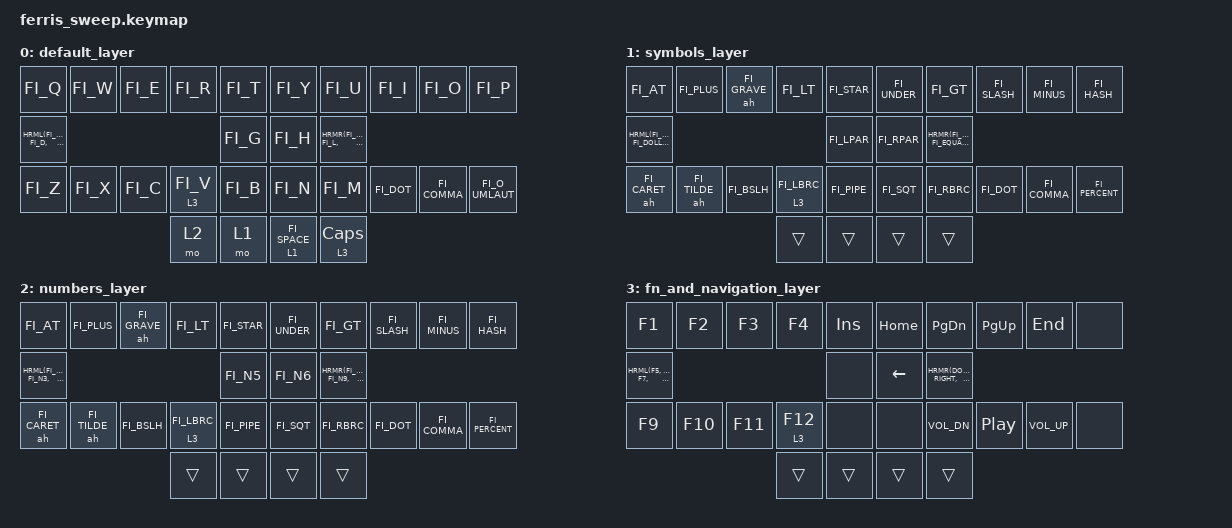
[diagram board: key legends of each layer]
// Copyright (c) 2022 The ZMK Contributors
// SPDX-License-Identifier: MIT

#include <behaviors.dtsi>
#include <dt-bindings/zmk/keys.h>
#include <dt-bindings/zmk/bt.h>
#include <dt-bindings/zmk/outputs.h>
#include "keys_fi.h"

// Home row mods
#define HRML(k1,k2,k3,k4) &ht LSHFT k1  &ht LCTRL k2  &ht LALT  k3  &ht LGUI  k4
#define HRMR(k1,k2,k3,k4) &ht RGUI  k1  &ht RALT  k2  &ht RCTRL k3  &ht RSHFT k4

&caps_word {
    continue-list = <UNDERSCORE MINUS BACKSPACE DELETE>;
};

/ {
    behaviors {
        ht: hold_tap {
            compatible = "zmk,behavior-hold-tap";
            #binding-cells = <2>;
            flavor = "balanced";
            tapping-term-ms = <200>;
            quick-tap-ms = <200>;
            require-prior-idle-ms = <100>;
            bindings = <&kp>, <&kp>;
        };
    };

    combos {
        compatible = "zmk,combos";
        combo_esc {
            timeout-ms = <40>;
            key-positions = <1 2>;
            bindings = <&kp ESC>;
            require-prior-idle-ms = <140>;
        };
        combo_tab {
            timeout-ms = <40>;
            key-positions = <11 12>;
            bindings = <&kp TAB>;
            require-prior-idle-ms = <140>;
        };
        combo_bspc {
            timeout-ms = <40>;
            key-positions = <7 8>;
            bindings = <&kp BSPC>;
            require-prior-idle-ms = <140>;
        };
        combo_enter {
            timeout-ms = <40>;
            key-positions = <17 18>;
            bindings = <&kp ENTER>;
            require-prior-idle-ms = <140>;
        };
        combo_del {
            timeout-ms = <40>;
            key-positions = <27 28>;
            bindings = <&kp DEL>;
            require-prior-idle-ms = <140>;
        };
    };

    macros {
        ah: accent_hack {
            compatible = "zmk,behavior-macro-one-param";
            #binding-cells = <1>;
            bindings = <&macro_param_1to1>, <&kp MACRO_PLACEHOLDER &kp FI_SPACE>;
        };
    };
    keymap {
        compatible = "zmk,keymap";
        default_layer {
            bindings = <
        //╭─────────────┬─────────────┬─────────────┬─────────────┬─────────────╮   ╭─────────────┬─────────────┬─────────────┬─────────────┬─────────────╮
            &kp FI_Q      &kp FI_W      &kp FI_E      &kp FI_R      &kp FI_T          &kp FI_Y      &kp FI_U      &kp FI_I      &kp FI_O      &kp FI_P
        //├─────────────┼─────────────┼─────────────┼─────────────┼─────────────┤   ├─────────────┼─────────────┼─────────────┼─────────────┼─────────────┤
            HRML(FI_A,    FI_S,         FI_D,         FI_F)         &kp FI_G          &kp FI_H      HRMR(FI_J,    FI_K,         FI_L,         FI_A_UMLAUT)
        //├─────────────┼─────────────┼─────────────┼─────────────┼─────────────┤   ├─────────────┼─────────────┼─────────────┼─────────────┼─────────────┤
            &kp FI_Z      &kp FI_X      &kp FI_C      &lt 3 FI_V    &kp FI_B          &kp FI_N      &kp FI_M      &kp FI_DOT    &kp FI_COMMA  &kp FI_O_UMLAUT
        //╰─────────────┴─────────────┴─────────────┼─────────────┼─────────────┤   ├─────────────┼─────────────┼─────────────┴─────────────┴─────────────╯
                                                      &mo 2         &mo 1             &lt 1 FI_SPACE  &lt 3 CAPSLOCK
        //                                          ╰─────────────┴─────────────╯   ╰─────────────┴─────────────╯
            >;
        };

        symbols_layer {
            bindings = <
        //╭─────────────┬─────────────┬─────────────┬─────────────┬─────────────╮   ╭─────────────┬─────────────┬─────────────┬─────────────┬─────────────╮
        //│  @          │  +          │  `          │  <          │   *         │   │  _          │  >          │  /          │  -          │  #          │
            &kp FI_AT     &kp FI_PLUS   &ah FI_GRAVE  &kp FI_LT     &kp FI_STAR       &kp FI_UNDER  &kp FI_GT    &kp FI_SLASH  &kp FI_MINUS   &kp FI_HASH
        //├─────────────┼─────────────┼─────────────┼─────────────┼─────────────┤   ├─────────────┼─────────────┼─────────────┼─────────────┼─────────────┤
        //│  !          │  &          │  $          │  [          │  (          │   │  ]          │  )          │  "          │  =          │  ?          │
            HRML(FI_EXCL, FI_AMPS,      FI_DOLLAR,    FI_LBKT)      &kp FI_LPAR       &kp FI_RPAR   HRMR(FI_RBKT, FI_DQT,       FI_EQUAL,     FI_QMARK)
        //├─────────────┼─────────────┼─────────────┼─────────────┼─────────────┤   ├─────────────┼─────────────┼─────────────┼─────────────┼─────────────┤
        //│  ^          │  ~          │  \          │  {          │  |          │   │  '          │  }          │  .          │  ,          │   %         │
            &ah FI_CARET  &ah FI_TILDE   &kp FI_BSLH  &lt 3 FI_LBRC &kp FI_PIPE       &kp FI_SQT    &kp FI_RBRC   &kp FI_DOT   &kp FI_COMMA  &kp FI_PERCENT
        //╰─────────────┴─────────────┴─────────────┼─────────────┼─────────────┤   ├─────────────┼─────────────┼─────────────┴─────────────┴─────────────╯
                                                      &trans        &trans            &trans        &trans
        //                                          ╰─────────────┴─────────────╯   ╰─────────────┴─────────────╯
            >;
        };

        numbers_layer {
            bindings = <
        //╭─────────────┬─────────────┬─────────────┬─────────────┬─────────────╮   ╭─────────────┬─────────────┬─────────────┬─────────────┬─────────────╮
        //│  @          │  +          │  `          │  <          │   *         │   │  _          │  >          │  /          │  -          │  #          │
            &kp FI_AT     &kp FI_PLUS   &ah FI_GRAVE  &kp FI_LT     &kp FI_STAR       &kp FI_UNDER  &kp FI_GT    &kp FI_SLASH  &kp FI_MINUS   &kp FI_HASH
        //├─────────────┼─────────────┼─────────────┼─────────────┼─────────────┤   ├─────────────┼─────────────┼─────────────┼─────────────┼─────────────┤
        //│  1          │  2          │  3          │  4          │  5          │   │  6          │  7          │  8          │  9          │   0         │
            HRML(FI_N1,   FI_N2,        FI_N3,        FI_N4)        &kp FI_N5         &kp FI_N6     HRMR(FI_N7,   FI_N8,        FI_N9,        FI_N0)
        //├─────────────┼─────────────┼─────────────┼─────────────┼─────────────┤   ├─────────────┼─────────────┼─────────────┼─────────────┼─────────────┤
        //│  ^          │  ~          │  \          │  {          │  |          │   │  '          │  }          │  .          │  ,          │   %         │
            &ah FI_CARET  &ah FI_TILDE   &kp FI_BSLH  &lt 3 FI_LBRC &kp FI_PIPE       &kp FI_SQT    &kp FI_RBRC   &kp FI_DOT   &kp FI_COMMA  &kp FI_PERCENT
        //╰─────────────┴─────────────┴─────────────┼─────────────┼─────────────┤   ├─────────────┼─────────────┼─────────────┴─────────────┴─────────────╯
                                                      &trans        &trans            &trans        &trans
        //                                          ╰─────────────┴─────────────╯   ╰─────────────┴─────────────╯
            >;
        };

        fn_and_navigation_layer {
            bindings = <
        //╭─────────────┬─────────────┬─────────────┬─────────────┬─────────────╮   ╭─────────────┬─────────────┬─────────────┬─────────────┬─────────────╮
            &kp F1        &kp F2        &kp F3        &kp F4        &kp INS           &kp HOME      &kp PG_DN     &kp PG_UP     &kp END       &none
        //├─────────────┼─────────────┼─────────────┼─────────────┼─────────────┤   ├─────────────┼─────────────┼─────────────┼─────────────┼─────────────┤
            HRML(F5,      F6,           F7,           F8)           &none             &kp LEFT      HRMR(DOWN,     UP,          RIGHT,        RSHFT)
        //├─────────────┼─────────────┼─────────────┼─────────────┼─────────────┤   ├─────────────┼─────────────┼─────────────┼─────────────┼─────────────┤
            &kp F9        &kp F10       &kp F11       &lt 3 F12     &none             &none         &kp C_VOL_DN  &kp C_PLAY_PAUSE &kp C_VOL_UP  &none
        //╰─────────────┴─────────────┴─────────────┼─────────────┼─────────────┤   ├─────────────┼─────────────┼─────────────┴─────────────┴─────────────╯
                                                      &trans        &trans            &trans        &trans
        //                                          ╰─────────────┴─────────────╯   ╰─────────────┴─────────────╯
            >;
        };
    };
};
